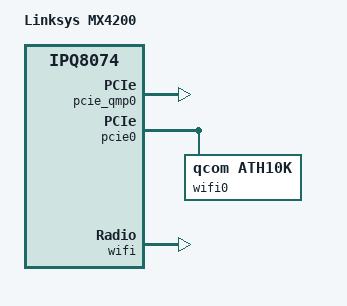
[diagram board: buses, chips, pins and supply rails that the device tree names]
// SPDX-License-Identifier: GPL-2.0-or-later OR MIT
/* Copyright (c) 2021, Robert Marko <robimarko@gmail.com> */

/dts-v1/;

#include "ipq8074-mx4200.dtsi"
#include <dt-bindings/leds/common.h>

/ {
	model = "Linksys MX4200";
	compatible = "linksys,mx4200", "qcom,ipq8074";

	leds@62 {
		compatible = "nxp,pca9633";
		#address-cells = <1>;
		#size-cells = <0>;
		reg = <0x62>;

		/* RGB? */
		led@0 {
			reg = <0>;
			color = <LED_COLOR_ID_RED>;
			function = LED_FUNCTION_POWER;
		};

		led@1 {
			reg = <1>;
			color = <LED_COLOR_ID_GREEN>;
			function = LED_FUNCTION_POWER;
		};

		led_system_blue: led@2 {
			reg = <2>;
			color = <LED_COLOR_ID_BLUE>;
			function = LED_FUNCTION_POWER;
			linux,default-trigger = "default-on";
		};
	};
};

&pcie_qmp0 {
	status = "okay";
};

&pcie0 {
	status = "okay";

	perst-gpio = <&tlmm 52 GPIO_ACTIVE_HIGH>;

	bridge@0,0 {
		reg = <0x00000000 0 0 0 0>;
		#address-cells = <3>;
		#size-cells = <2>;
		ranges;

		wifi0: wifi@1,0 {
			status = "okay";

			compatible = "qcom,ath10k";
			reg = <0x00010000 0 0 0 0>;

			qcom,ath10k-calibration-variant = "Linksys-MX4200";
			nvmem-cell-names = "calibration";
			nvmem-cells = <&caldata_qca9889>;
		};
	};
};

&wifi {
	qcom,ath11k-calibration-variant = "Linksys-MX4200";
};
